# WKUP_CTRL_MMR0_WKUP_CTRL_MMR_CFG0_43000000h register map
Vendor: Texas Instruments
Registers are 32-bit, read-write, reset 0x0 unless marked. A register's access mark holds for its fields unless they carry their own. Offsets are as the file gives them; [hi:lo] are bit positions; {n}, {i} and the like mark numbered series.

## wkup_ctrl_mmr_CFG0 (part 3 of 3)
0x18368 WKUP_CTRL_MMRCFG0_IMMED_WAKE_TIMEOUT reset 0xEA — Determines the length of the timing window during which a monitored wakeup event will generate an IPOR. This ensures wakeup events occurring soon after PMIC_EN deactivation but before IORET state entry are recognized. After this window has expired, the external PMIC is expected to generate a POR based on PMIC_EN activation.The ImmediateWakeup Timeout window is disabled (no IPOR generated) if the wake_timeout_dis in WAKE_EVT_MON_CTRL is 1.
  [15:0] IMMED_WAKE_TIMEOUT_TIMEOUT_LENGTH — Specifies the number of HFOSC0 clock cycles during which wake monitoring logic will issue an internal POR. This timeout value must exceed the PMIC glitch filtering window for its PMIC_EN input. (Default value is 9 �s at 26 MHz HFOSC0) Reset Source: mod_por_rst_n
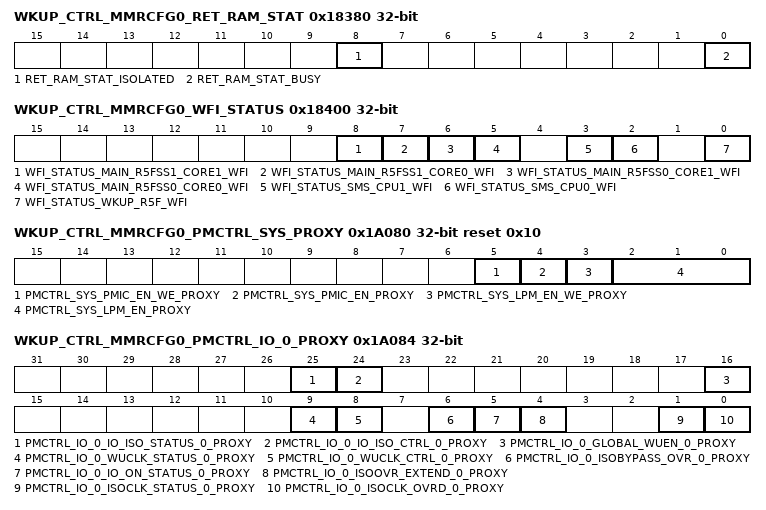
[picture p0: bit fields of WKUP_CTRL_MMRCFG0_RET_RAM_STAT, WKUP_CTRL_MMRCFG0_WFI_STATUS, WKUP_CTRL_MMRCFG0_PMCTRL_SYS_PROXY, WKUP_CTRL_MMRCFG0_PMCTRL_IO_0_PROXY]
0x18380 WKUP_CTRL_MMRCFG0_RET_RAM_STAT ro — Shows the Retention RAM Status
  [8] RET_RAM_STAT_ISOLATED — Indicates Retention RAM isolation state (when busy=0)Field values (others are reserved):1'b0 - RAM is not isolated1'b1 - RAM is isolated Reset Source: mod_por_rst_n
  [0] RET_RAM_STAT_BUSY — Indicates that Retention RAM state is transitioning. The RAM must not be accessed or the isolation powerdown sequence continued while busy=1Field values (others are reserved):1'b0 - RAM is in isolation state indicated by the isolated bit1'b1 - RAM isolation state is transitioning - do not access Reset Source: mod_por_rst_n
0x18400 WKUP_CTRL_MMRCFG0_WFI_STATUS ro — Allows inspection of WFI Status of all CPU Cores
  [8] WFI_STATUS_MAIN_R5FSS1_CORE1_WFI — WFI status of MAIN Cortex R5F_1 Core 1 (only valid when core is out of reset)Field values (others are reserved):1'b0 - UNKNOWN1'b1 - WFI_ACTIVE Reset Source: mod_por_rst_n
  [7] WFI_STATUS_MAIN_R5FSS1_CORE0_WFI — WFI status of MAIN Cortex R5F_1 Core 0 (only valid when core is out of reset)Field values (others are reserved):1'b0 - UNKNOWN1'b1 - WFI_ACTIVE Reset Source: mod_por_rst_n
  [6] WFI_STATUS_MAIN_R5FSS0_CORE1_WFI — WFI status of MAIN Cortex R5F_0 Core 0 (only valid when core is out of reset)Field values (others are reserved):1'b0 - UNKNOWN1'b1 - WFI_ACTIVE Reset Source: mod_por_rst_n
  [5] WFI_STATUS_MAIN_R5FSS0_CORE0_WFI — WFI status of MAIN Cortex R5F_0 Core 0 (only valid when core is out of reset)Field values (others are reserved):1'b0 - UNKNOWN1'b1 - WFI_ACTIVE Reset Source: mod_por_rst_n
  [3] WFI_STATUS_SMS_CPU1_WFI — WFI status of SMS Cortex M4F1 (only valid when CPU is out of reset)Field values (others are reserved):1'b0 - UNKNOWN1'b1 - WFI_ACTIVE Reset Source: mod_por_rst_n
  [2] WFI_STATUS_SMS_CPU0_WFI — WFI status of SMS Cortex M4F0 (only valid when CPU is out of reset)Field values (others are reserved):1'b0 - UNKNOWN1'b1 - WFI_ACTIVE Reset Source: mod_por_rst_n
  [0] WFI_STATUS_WKUP_R5F_WFI — WFI status of Device Manager Cortex R5F (only valid when CPU is out of reset)Field values (others are reserved):1'b0 - UNKNOWN1'b1 - WFI_ACTIVE Reset Source: mod_por_rst_n
0x18420 WKUP_CTRL_MMRCFG0_DS_MAIN reset 0xF — Reset Control and Main Power Domain Control
  [3:0] DS_MAIN_POR_PDOFF — Signal Puts main SMS, DebugSS and MainIP Power Domains into Power Off state, and asserts Main Power On Reset.Field values (others are reserved):4'b0110 - Off4'b1111 - On Reset Source: mcu_chip1_rst_n
0x18440 WKUP_CTRL_MMRCFG0_DS_DM_RESET reset 0xF — Reset Isolation for the Device Manager
  [3:0] DS_DM_RESET_MASK — Signal used to mask main domain resets from Device Manager / Wakeup and MCU IpsField values (others are reserved):4'b0110 - Masked4'b1111 - UnMasked Reset Source: mcu_chip1_rst_n
0x18460 WKUP_CTRL_MMRCFG0_DS_USB0_RESET reset 0xF — Reset Isolation for the USB0 Subsystem
  [3:0] DS_USB0_RESET_MASK — Signal used to block reset to the USBSS0Field values (others are reserved):4'b0110 - Masked4'b1111 - UnMasked Reset Source: mcu_chip1_rst_n
0x184A0 WKUP_CTRL_MMRCFG0_DM_GRP_CLKSTOP_REQ — Initiate Clockstop Request Sequence on WKUP Peripherals Activated in DM_CLKSTOP_EN
  [0] DM_GRP_CLKSTOP_REQ_REQ — Controls Assertion of Clockstop Request to IPs participating in Clockstop Req GroupField values (others are reserved):1'b0 - DEASSERT_REQ1'b1 - ASSERT_REQ Reset Source: mod_por_rst_n
0x18500 WKUP_CTRL_MMRCFG0_DEVICE_TYPE ro — Device Type as Decoded by SMS
  [7:4] DEVICE_TYPE_SMS_DEV_TYPE — Type of device reported by SMS. Values not listed should be interpreted as BAD.Field values (others are reserved):4'b0101 - DT_TEST4'b1001 - DT_EMU4'b1010 - DT_HS4'b0011 - DT_GP Reset Source: mod_por_rst_n
0x19008 WKUP_CTRL_MMRCFG0_LOCK6_KICK0
  [31:0] LOCK6_KICK0 — - KICK0 component Reset Source: mod_g_rst_n
0x1900C WKUP_CTRL_MMRCFG0_LOCK6_KICK1
  [31:0] LOCK6_KICK1 — - KICK1 component Reset Source: mod_g_rst_n
{0x19100+4i} WKUP_CTRL_MMRCFG0_CLAIMREG_P6_R{i}_READONLY ro (i=0..10)
  [31:0] CLAIMREG_P6_R{i}_READONLY — Claim bits for Partition 6 Reset Source: mod_g_rst_n
0x1A080 WKUP_CTRL_MMRCFG0_PMCTRL_SYS_PROXY reset 0x10 — Controls operation of the PMIC_LPM_EN pin
  [5] PMCTRL_SYS_PMIC_EN_WE_PROXY — Unused Field - Value is Don't Care Reset Source: mod_g_rst_n
  [4] PMCTRL_SYS_PMIC_EN_PROXY — Controls state of PMIC_LPM_EN_OUT when LPM_EN[2:0] is 000 Reset Source: mod_g_rst_n
  [3] PMCTRL_SYS_LPM_EN_WE_PROXY — Unused Field - Value is Don't Care Reset Source: mod_g_rst_n
  [2:0] PMCTRL_SYS_LPM_EN_PROXY — Controls whether PMIC_LPM_EN_OUT is driven by the pmic_en bit. Field values (others are reserved):3'b000 - PMIC_LPM_EN_OUT controlled by pmic_en bit. Reset Source: mod_g_rst_n
0x1A084 WKUP_CTRL_MMRCFG0_PMCTRL_IO_0_PROXY access per field — This register is writable only when LOCK6-KICK0:1 are unlocked
  [25] PMCTRL_IO_0_IO_ISO_STATUS_0_PROXY ro — IO ISO Status. Read 0: IO isolation not active. Read 1: IO isolation active.Reflects value of SMS input port io_isoack coming back fromIO pad ring. Reset Source: mod_g_rst_n
  [24] PMCTRL_IO_0_IO_ISO_CTRL_0_PROXY rw — IO ISO control. Writing this bit to 1 will kick off IO isolation. Reset Source: mod_g_rst_n
  [16] PMCTRL_IO_0_GLOBAL_WUEN_0_PROXY rw — Global IO wakeup enable. This is a gating condition to allindividual IO WUEN coming from control module. Gating isdone in the Io Logiclogic. 0:All individual IO WUEN are gated in the IO logic (override to 0). 1: All individual IO WUEN from control module are going to IOs.Map to SMS input port io_globalwkupen Reset Source: mod_g_rst_n
  [9] PMCTRL_IO_0_WUCLK_STATUS_0_PROXY ro — Reflects value of DM input port io_wuclkack coming backfrom IO pad ring. Reset Source: mod_g_rst_n
  [8] PMCTRL_IO_0_WUCLK_CTRL_0_PROXY rw — Direct control on WUCLKIN signal to IO pad ring.0:WUCLKINsignal is driven to 0.IO wakeup daisy chain is functional as wellas IO whose wakeup feature is enabled. 1:WUCLKIN signal is driven to 1. IO wakeup daisy chain is reset and is latching current pad states and WUEN inputs. Reset Source: mod_g_rst_n
  [6] PMCTRL_IO_0_ISOBYPASS_OVR_0_PROXY rw — This MMR bit drives directly DM output port io_isobypassundefined. Reset Source: mod_g_rst_n
  [5] PMCTRL_IO_0_IO_ON_STATUS_0_PROXY ro — Gives the functional status of the IO ring. Read 0: Part or all of the IOs are not in the ON state that is are in isolation state.Read 1: All IOs are in the ON state.io_on_status = assign 1 if (io_iso == 0 & io_isoack==0 &io_iso_clk == 0 & io_isoclk_ack = 0 ) else 0; Reset Source: mod_g_rst_n
  [4] PMCTRL_IO_0_ISOOVR_EXTEND_0_PROXY rw — This drives the SOC chain ISO-OVERRIDE global control.This bit drives directly the DM output port io_isoovrundefined. Atthe SOC level it is used to enable when 1 or gate-off when 0,the individual ISOOR for each IO. This operates as a globalenable/disable for the individual IOs.Control for IO isolation extension.'0' IO isolation is not extended. Transition happens as soon asautomatic restore is completed.'1' IO isolation is extended. The IOs whose ISOOVR bits havebeen individually set in their PADCFG MMRs will all get its IOisolation extended beyond the point when the initial IO daisychain isolation is released. Reset Source: mod_g_rst_n
  [1] PMCTRL_IO_0_ISOCLK_STATUS_0_PROXY ro — Reflects value of DM input port io_isoclkack coming backfrom IO pad ring. Reset Source: mod_g_rst_n
  [0] PMCTRL_IO_0_ISOCLK_OVRD_0_PROXY rw — Override control on ISOCLKIN signal to IO pad ring.When not overridden this signal is controlled by hardware only.0 ISOCLKIN signal is not override.1 ISOCLKIN signal is overridden to active value ('1'). Reset Source: mod_g_rst_n
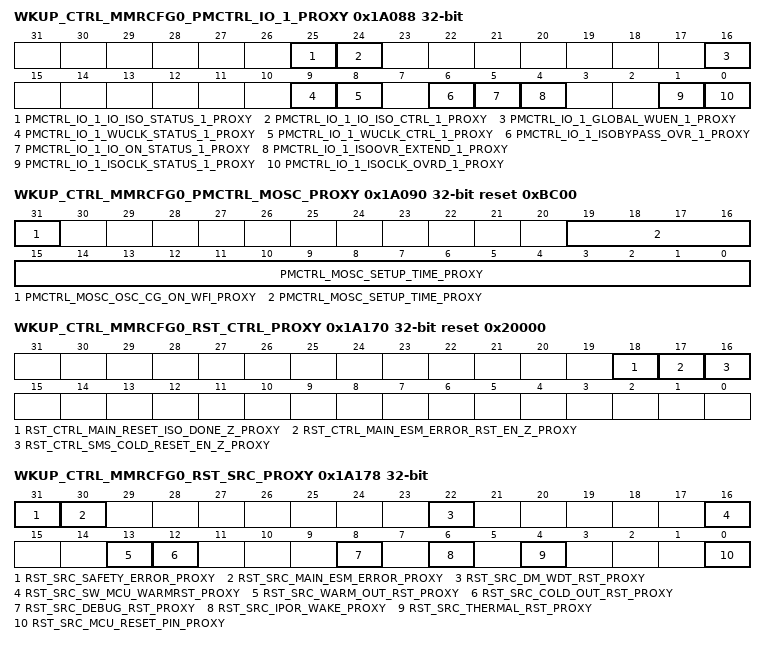
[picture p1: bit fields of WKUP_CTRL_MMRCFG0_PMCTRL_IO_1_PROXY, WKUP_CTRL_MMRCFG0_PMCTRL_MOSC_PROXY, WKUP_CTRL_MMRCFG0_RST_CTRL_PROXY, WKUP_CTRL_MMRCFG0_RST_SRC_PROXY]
0x1A088 WKUP_CTRL_MMRCFG0_PMCTRL_IO_1_PROXY access per field — This register is writable only when LOCK6-KICK0:1 are unlocked
  [25] PMCTRL_IO_1_IO_ISO_STATUS_1_PROXY ro — IO ISO Status. Read 0: IO isolation not active. Read 1: IO isolation active.Reflects value of DM input port io_isoack coming back fromIO pad ring. Reset Source: mod_g_rst_n
  [24] PMCTRL_IO_1_IO_ISO_CTRL_1_PROXY rw — IO ISO control. Writing this bit to 1 will kick off IO isolation. Reset Source: mod_g_rst_n
  [16] PMCTRL_IO_1_GLOBAL_WUEN_1_PROXY rw — Global IO wakeup enable. This is a gating condition to allindividual IO WUEN coming from control module. Gating isdone in the Spinner logic. 0:All individual IO WUEN are gatedin the Spinner logic (override to 0). 1: All individual IO WUENfrom control module are going to Ios.Map to DM input port io_globalwkupen Reset Source: mod_g_rst_n
  [9] PMCTRL_IO_1_WUCLK_STATUS_1_PROXY ro — Reflects value of DM input port io_wuclkack coming backfrom IO pad ring. Reset Source: mod_g_rst_n
  [8] PMCTRL_IO_1_WUCLK_CTRL_1_PROXY rw — Direct control on WUCLKIN signal to IO pad ring.0:WUCLKINsignal is driven to 0.IO wakeup daisy chain is functional as wellas IO whose wakeup feature is enabled. 1:WUCLKIN signal is driven to 1. IO wakeup daisy chain is reset and is latching current pad states and WUEN inputs. Reset Source: mod_g_rst_n
  [6] PMCTRL_IO_1_ISOBYPASS_OVR_1_PROXY rw — This MMR bit drives directly DM output port io_isobypassundefined. Reset Source: mod_g_rst_n
  [5] PMCTRL_IO_1_IO_ON_STATUS_1_PROXY ro — Gives the functional status of the IO ring. Read 0: Part or all ofthe Ios are not in the ON state that is are in isolation state.Read 1: All Ios are in the ON state.io_on_status = assign 1 if (io_iso == 0 & io_isoack==0 &io_iso_clk == 0 & io_isoclk_ack = 0 ) else 0; Reset Source: mod_g_rst_n
  [4] PMCTRL_IO_1_ISOOVR_EXTEND_1_PROXY rw — This drives the SOC chain ISO-OVERRIDE global control.This bit drives directly the DM output port io_isoovrundefined. Atthe SOC level it is used to enable when 1 or gate-off when 0,the individual ISOOR for each IO. This operates as a globalenable/disable for the individual IOs.Control for IO isolation extension.'0' IO isolation is not extended. Transition happens as soon asautomatic restore is completed.'1' IO isolation is extended. The IOs whose ISOOVR bits havebeen individually set in their PADCFG MMRs will all get its IOisolation extended beyond the point when the initial IO daisychain isolation is released. Reset Source: mod_g_rst_n
  [1] PMCTRL_IO_1_ISOCLK_STATUS_1_PROXY ro — Reflects value of DM input port io_isoclkack coming backfrom IO pad ring. Reset Source: mod_g_rst_n
  [0] PMCTRL_IO_1_ISOCLK_OVRD_1_PROXY rw — Override control on ISOCLKIN signal to IO pad ring.When not overridden this signal is controlled by hardware only.0 ISOCLKIN signal is not override.1 ISOCLKIN signal is overridden to active value ('1'). Reset Source: mod_g_rst_n
0x1A090 WKUP_CTRL_MMRCFG0_PMCTRL_MOSC_PROXY reset 0xBC00 — This register is writable only when LOCK6-KICK0:1 are unlocked
  [31] PMCTRL_MOSC_OSC_CG_ON_WFI_PROXY — To clock gate the main HFOSC, DM sets this bit then enters the WFI state at which time the HFOSC will be gated. Field values (others are reserved):1'b0 - INACTIVE1'b1 - ACTIVE Reset Source: mod_g_rst_n
  [19:0] PMCTRL_MOSC_SETUP_TIME_PROXY — Number of HFOSC clock cycles before HFOSC clock is ungated to the SOC (allows the HFOSC time to stabilize after starting up, before the SOC is clocked). Reset Source: mod_g_rst_n
0x1A098 WKUP_CTRL_MMRCFG0_PM_MISC_STATUS_PROXY ro — Reflects the progress of the request to clock-gate HFOSCvia MMR PMCTRL_MOSCundefined.
  [1:0] PM_MISC_STATUS_OSC_CG_STAT_PROXY — HFOSC Clock Gating StateField values (others are reserved):2'b00 - HFOSC_OFF2'b01 - HFOSC_OFF2ON (transition state)2'b10 - HFOSC_ON2OFF (transition state)2'b11 - HFOSC_ON Reset Source: mod_g_rst_n
0x1A170 WKUP_CTRL_MMRCFG0_RST_CTRL_PROXY reset 0x20000 — Controls Reset Assertion and Propogation
  [18] RST_CTRL_MAIN_RESET_ISO_DONE_Z_PROXY — Blocks Main Domain Warm Reset.Field values (others are reserved):1'b0 - PROPOGATE1'b1 - BLOCK Reset Source: main_chip1_rst_n
  [17] RST_CTRL_MAIN_ESM_ERROR_RST_EN_Z_PROXY — Block Reset of Main by ESMField values (others are reserved):1'b0 - PROPOGATE1'b1 - BLOCK Reset Source: main_chip1_rst_n
  [16] RST_CTRL_SMS_COLD_RESET_EN_Z_PROXY — Block Reset of Main by SMSField values (others are reserved):1'b0 - PROPOGATE1'b1 - BLOCK Reset Source: main_chip1_rst_n
0x1A174 WKUP_CTRL_MMRCFG0_RST_STAT_PROXY ro — Reset Status
  [0] RST_STAT_MCU_RESET_ISO_DONE_Z_PROXY — Indicates MCU Domain is in Reset Isolation When Active (Low)Field values (others are reserved):1'b0 - ISOLATION1'b1 - PASS_THROUGH Reset Source: main_chip1_rst_n
0x1A178 WKUP_CTRL_MMRCFG0_RST_SRC_PROXY ro — Captures Reason for Warm and Main Domain Power On ResetsRead Only Mirror of MCU CTRL MMR version. Clearing these bits must be done through the MCU CTRL MMR.
  [31] RST_SRC_SAFETY_ERROR_PROXY — Reset Caused by MCU ESM Error. Field values (others are reserved):1'b0 - UNKNOWN1'b1 - DETECTED Reset Source: main_chip1_rst_n
  [30] RST_SRC_MAIN_ESM_ERROR_PROXY — Reset Caused by Main ESM Error. Field values (others are reserved):1'b0 - UNKNOWN1'b1 - DETECTED Reset Source: main_chip1_rst_n
  [22] RST_SRC_DM_WDT_RST_PROXY — Watchdog Initiated Reset. Field values (others are reserved):1'b0 - UNKNOWN1'b1 - DETECTED Reset Source: main_chip1_rst_n
  [16] RST_SRC_SW_MCU_WARMRST_PROXY — Software Warm Reset. Field values (others are reserved):1'b0 - UNKNOWN1'b1 - DETECTED Reset Source: main_chip1_rst_n
  [13] RST_SRC_WARM_OUT_RST_PROXY — SMS Warm Reset. Field values (others are reserved):1'b0 - UNKNOWN1'b1 - DETECTED Reset Source: main_chip1_rst_n
  [12] RST_SRC_COLD_OUT_RST_PROXY — SMS Cold Reset. When set, indicates that a SMS Cold reset occurred and reset either MAIN or MCU domains (or both).Field values (others are reserved):1'b0 - UNKNOWN1'b1 - DETECTED Reset Source: main_chip1_rst_n
  [8] RST_SRC_DEBUG_RST_PROXY — Debug Subsystem Initiated Reset. Field values (others are reserved):1'b0 - UNKNOWN1'b1 - DETECTED Reset Source: main_chip1_rst_n
  [6] RST_SRC_IPOR_WAKE_PROXY — Wake Event Monitor Internal Power On Reset.Field values (others are reserved):1'b0 - UNKNOWN1'b1 - DETECTED Reset Source: main_chip1_rst_n
  [4] RST_SRC_THERMAL_RST_PROXY — Thermal Reset. Field values (others are reserved):1'b0 - UNKNOWN1'b1 - DETECTED Reset Source: main_chip1_rst_n
  [0] RST_SRC_MCU_RESET_PIN_PROXY — Rest Caused by MCU Reset Pin. Field values (others are reserved):1'b0 - UNKNOWN1'b1 - DETECTED Reset Source: main_chip1_rst_n
0x1A17C WKUP_CTRL_MMRCFG0_RST_MAGIC_WORD_PROXY ro — Read Only Mirror of MCU CTRL MMR version.After an MCU_PORz reset this bit field resets to 0x00000000. While this bit field remains 0x00000000 any warm reset from the Main Domain also propagates through the MCU domain.If the application does not require reset isolation of the MCU domain, it may leave this bit field with a value of 0x00000000.If the application does require reset isolation of the MCU domain after the initial boot, then the R5FSS CPU must write a nonzero value to the magic word. The actual value is left to software and different values maybe used to convey information, but in order to isolate the MCU domain from all Main domain warm reset sources that trigger main_resetz, the value must be non-zero.If the value is nonzero and one of the Main domain warm reset sources triggers main_resetz occurs in the main domain, the R5FSS will not be reset. The Main domain bootloader must read this valueto determine that the R5FSS is already initialized, and has configured reset isolation. The Main domain bootloader then also skips any initialization steps involving bootstrapping the R5FSS as it is is already running.Note that MCU_PORz reset is never blocked by a nonzero magic word.
  [31:0] RST_MAGIC_WORD_MCU_MAGIC_WORD_PROXY — Magic Word Indicating Status of MCU Subsystem Boot Reset Source: main_chip1_rst_n
0x1A180 WKUP_CTRL_MMRCFG0_WKUP0_EN_PROXY — Selects active wake-up sources
  [31:0] WKUP0_EN_WKUPEN_PROXY — Enables Wakeup from on-chip sources. In addition to values listed, any OR combination of the values is also valid.Field values (others are reserved):32'h00000001 - WKUP_I2C032'h00000002 - WKUP_USART032'h00000004 - MCU_GPIO032'h00000008 - DEBUGundefined - undefined32'h00000020 - WKUP_TIMER032'h00000040 - WKUP_TIMER132'h00000080 - WKUP_RTC32'h00000100 - MAIN_RESET_REQz32'h00000200 - USB0_IN_BANDundefined - undefined32'h00010000 - MAIN_IO_DAISY_CHAIN32'h00020000 - MCU_IO_DAISY_CHAIN32'h00040000 - CANUART_IO_DAISY_CHAIN Reset Source: mod_g_rst_n
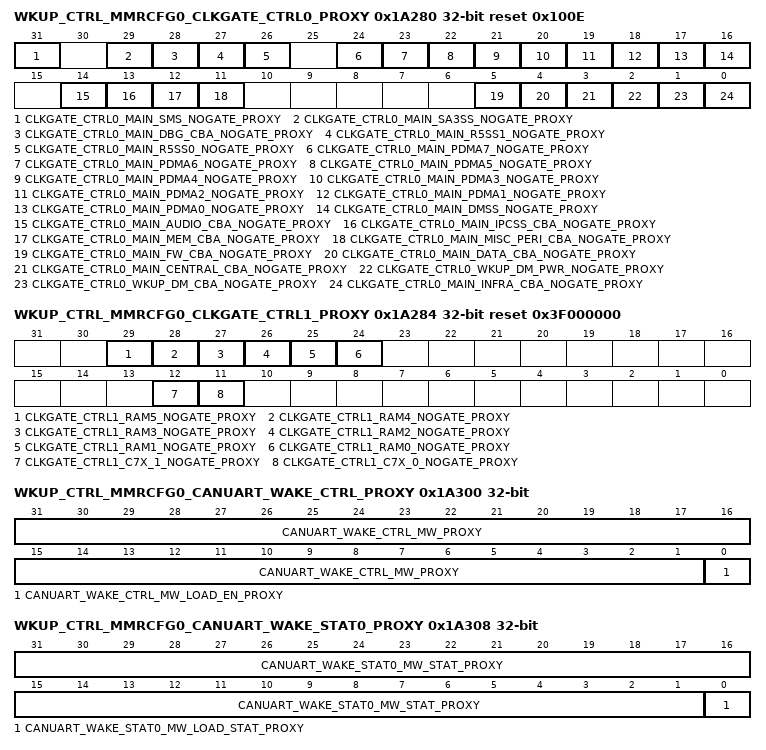
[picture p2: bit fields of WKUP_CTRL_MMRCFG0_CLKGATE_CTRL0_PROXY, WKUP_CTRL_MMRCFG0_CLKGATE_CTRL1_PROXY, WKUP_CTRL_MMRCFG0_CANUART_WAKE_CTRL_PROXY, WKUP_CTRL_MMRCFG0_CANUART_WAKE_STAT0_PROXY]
0x1A280 WKUP_CTRL_MMRCFG0_CLKGATE_CTRL0_PROXY reset 0x100E — Controls the power clock gating feature of modules and busses
  [31] CLKGATE_CTRL0_MAIN_SMS_NOGATE_PROXY — MAIN domain SMS auto clock gate on idle disable. Field values (others are reserved):1'b0 - Auto clock gating enabled1'b1 - Auto clock gating disabled Reset Source: mod_por_rst_n
  [29] CLKGATE_CTRL0_MAIN_SA3SS_NOGATE_PROXY — MAIN domain SA3SS auto clock gate on idle disable. Field values (others are reserved):1'b0 - Auto clock gating enabled1'b1 - Auto clock gating disabled Reset Source: mod_por_rst_n
  [28] CLKGATE_CTRL0_MAIN_DBG_CBA_NOGATE_PROXY — MAIN domain Debug CBASS auto clock gate on idle disable. Field values (others are reserved):1'b0 - Auto clock gating enabled1'b1 - Auto clock gating disabled Reset Source: mod_por_rst_n
  [27] CLKGATE_CTRL0_MAIN_R5SS1_NOGATE_PROXY — MAIN domain R5SS1 auto clock gate on idle disableField values (others are reserved):1'b0 - Auto clock gating enabled1'b1 - Auto clock gating disabled Reset Source: mod_por_rst_n
  [26] CLKGATE_CTRL0_MAIN_R5SS0_NOGATE_PROXY — MAIN domain R5SS0 auto clock gate on idle disableField values (others are reserved):1'b0 - Auto clock gating enabled1'b1 - Auto clock gating disabled Reset Source: mod_por_rst_n
  [24] CLKGATE_CTRL0_MAIN_PDMA7_NOGATE_PROXY — MAIN domain PDMA7 (ASRC11) auto clock gate on idle disable. Field values (others are reserved):1'b1 - Auto clock gating disabled Reset Source: mod_por_rst_n
  [23] CLKGATE_CTRL0_MAIN_PDMA6_NOGATE_PROXY — MAIN domain PDMA6 (ASRC0) auto clock gate on idle disable. Field values (others are reserved):1'b0 - Auto clock gating enabled1'b1 - Auto clock gating disabled1'b0 - Auto clock gating enabled Reset Source: mod_por_rst_n
  [22] CLKGATE_CTRL0_MAIN_PDMA5_NOGATE_PROXY — MAIN domain PDMA5 (ADC) auto clock gate on idle disable. Field values (others are reserved):1'b0 - Auto clock gating enabled1'b1 - Auto clock gating disabled Reset Source: mod_por_rst_n
  [21] CLKGATE_CTRL0_MAIN_PDMA4_NOGATE_PROXY — MAIN domain PDMA4 (SPI/MCAN 1) auto clock gate on idle disable. Field values (others are reserved):1'b0 - Auto clock gating enabled1'b1 - Auto clock gating disabled Reset Source: mod_por_rst_n
  [20] CLKGATE_CTRL0_MAIN_PDMA3_NOGATE_PROXY — MAIN domain PDMA3 (McASP1) auto clock gate on idle disable. Field values (others are reserved):1'b0 - Auto clock gating enabled1'b1 - Auto clock gating disabled Reset Source: mod_por_rst_n
  [19] CLKGATE_CTRL0_MAIN_PDMA2_NOGATE_PROXY — MAIN domain PDMA2 (McASP0) auto clock gate on idle disable. Field values (others are reserved):1'b0 - Auto clock gating enabled1'b1 - Auto clock gating disabled Reset Source: mod_por_rst_n
  [18] CLKGATE_CTRL0_MAIN_PDMA1_NOGATE_PROXY — MAIN domain PDMA1 (UART) auto clock gate on idle disable. Field values (others are reserved):1'b0 - Auto clock gating enabled1'b1 - Auto clock gating disabled Reset Source: mod_por_rst_n
  [17] CLKGATE_CTRL0_MAIN_PDMA0_NOGATE_PROXY — MAIN domain PDMA0 (SPI/MCAN 0) auto clock gate on idle disable. Field values (others are reserved):1'b0 - Auto clock gating enabled1'b1 - Auto clock gating disabled Reset Source: mod_por_rst_n
  [16] CLKGATE_CTRL0_MAIN_DMSS_NOGATE_PROXY — MAIN domain DMSS auto clock gate on idle disable. Field values (others are reserved):1'b0 - Auto clock gating enabled1'b1 - Auto clock gating disabled Reset Source: mod_por_rst_n
  [14] CLKGATE_CTRL0_MAIN_AUDIO_CBA_NOGATE_PROXY — MAIN domain Infrastructure bus (AUDIO) auto clock gate on idle disable. Field values (others are reserved):1'b0 - Auto clock gating enabled1'b1 - Auto clock gating disabled Reset Source: mod_por_rst_n
  [13] CLKGATE_CTRL0_MAIN_IPCSS_CBA_NOGATE_PROXY — MAIN domain Infrastructure CBASS auto clock gate on idle disable. Field values (others are reserved):1'b0 - Auto clock gating enabled1'b1 - Auto clock gating disabled Reset Source: mod_por_rst_n
  [12] CLKGATE_CTRL0_MAIN_MEM_CBA_NOGATE_PROXY — MAIN domain infrastructure bus (MEM) auto cloclk gate on idle disable Reset Source: mod_por_rst_n
  [11] CLKGATE_CTRL0_MAIN_MISC_PERI_CBA_NOGATE_PROXY — MAIN domain Infrastructure bus (Misc Peripheral) auto clock gate on idle disable. Field values (others are reserved):1'b0 - Auto clock gating enabled1'b1 - Auto clock gating disabled Reset Source: mod_por_rst_n
  [5] CLKGATE_CTRL0_MAIN_FW_CBA_NOGATE_PROXY — MAIN domain data bus auto clock gate on idle disable. Field values (others are reserved):1'b0 - Auto clock gating enabled1'b1 - Auto clock gating disabled Reset Source: mod_por_rst_n
  [4] CLKGATE_CTRL0_MAIN_DATA_CBA_NOGATE_PROXY — MAIN domain data bus auto clock gate on idle disable. Field values (others are reserved):1'b0 - Auto clock gating enabled1'b1 - Auto clock gating disabled Reset Source: mod_por_rst_n
  [3] CLKGATE_CTRL0_MAIN_CENTRAL_CBA_NOGATE_PROXY — WKUP domain Infrastructure ECC aggregator auto clock gate on idle disable. Field values (others are reserved):1'b0 - Auto clock gating enabled1'b1 - Auto clock gating disabled Reset Source: mod_por_rst_n
  [2] CLKGATE_CTRL0_WKUP_DM_PWR_NOGATE_PROXY — WKUP domain Device Manager auto clock gate on idle disable.Field values (others are reserved):1'b0 - Auto clock gating enabled1'b1 - Auto clock gating disabled Reset Source: mod_por_rst_n
  [1] CLKGATE_CTRL0_WKUP_DM_CBA_NOGATE_PROXY — WKUP domain device manager CBA auto clock gate on idle disable.Field values (others are reserved):1'b0 - Auto clock gating enabled1'b1 - Auto clock gating disabled Reset Source: mod_por_rst_n
  [0] CLKGATE_CTRL0_MAIN_INFRA_CBA_NOGATE_PROXY — MAIN domain Infrastructure bus auto clock gate on idle disable. Field values (others are reserved):1'b0 - Auto clock gating enabled1'b1 - Auto clock gating disabled Reset Source: mod_por_rst_n
0x1A284 WKUP_CTRL_MMRCFG0_CLKGATE_CTRL1_PROXY reset 0x3F000000 — Controls the power clock gating feature of modules and busses
  [29] CLKGATE_CTRL1_RAM5_NOGATE_PROXY — MAIN SRAM bank 5 auto clockgate on idle disableField values (others are reserved):1'b0 - Auto clock gating enabled1'b1 - Auto clock gating disabled Reset Source: mod_por_rst_n
  [28] CLKGATE_CTRL1_RAM4_NOGATE_PROXY — MAIN SRAM bank 4 auto clockgate on idle disableField values (others are reserved):1'b0 - Auto clock gating enabled1'b1 - Auto clock gating disabled Reset Source: mod_por_rst_n
  [27] CLKGATE_CTRL1_RAM3_NOGATE_PROXY — MAIN SRAM bank 5 auto clockgate on idle disableField values (others are reserved):1'b0 - Auto clock gating enabled1'b1 - Auto clock gating disabled Reset Source: mod_por_rst_n
  [26] CLKGATE_CTRL1_RAM2_NOGATE_PROXY — MAIN SRAM bank 2 auto clockgate on idle disableField values (others are reserved):1'b0 - Auto clock gating enabled1'b1 - Auto clock gating disabled Reset Source: mod_por_rst_n
  [25] CLKGATE_CTRL1_RAM1_NOGATE_PROXY — MAIN SRAM bank 1 auto clockgate on idle disableField values (others are reserved):1'b0 - Auto clock gating enabled1'b1 - Auto clock gating disabled Reset Source: mod_por_rst_n
  [24] CLKGATE_CTRL1_RAM0_NOGATE_PROXY — MAIN SRAM bank 0 auto clockgate on idle disableField values (others are reserved):1'b0 - Auto clock gating enabled1'b1 - Auto clock gating disabled Reset Source: mod_por_rst_n
  [12] CLKGATE_CTRL1_C7X_1_NOGATE_PROXY — C7x_1 auto clock gate on idle disable. Field values (others are reserved):1'b0 - Auto clock gating enabled1'b1 - Auto clock gating disabled Reset Source: mod_por_rst_n
  [11] CLKGATE_CTRL1_C7X_0_NOGATE_PROXY — C7x_0 auto clock gate on idle disable. Reset Source: mod_por_rst_n
0x1A300 WKUP_CTRL_MMRCFG0_CANUART_WAKE_CTRL_PROXY — Controls the operation of IO wakeup on the CANUART pins.
  [31:1] CANUART_WAKE_CTRL_MW_PROXY — CANUART IO magic word. The lower 23 bits determine if the device enters CANUART IO isolation when mw_load_en is set.If the lower 23 bits match the ACTIVATE value (0x5AAAAA), then CANUART IO Isolation is entered, any other value will prevent entry.The upper 8 bits of this register are software defined and do not determine whether or not CANUART IO isolation is entered. Field values (others are reserved):31'h005AAAAA - ACTIVATE31'h00000000 - DEACTIVATE Reset Source: mcu_chip1_rst_n
  [0] CANUART_WAKE_CTRL_MW_LOAD_EN_PROXY — Magic word load enableSetting this bit loads and locks the mw field for CANUART IO isolation. If the mw field matches ACTIVATE, CANUART IO Isolation is initiated.Field values (others are reserved):1'b0 - UNLOCK1'b1 - LOCK_AND_LOAD Reset Source: mcu_chip1_rst_n
0x1A308 WKUP_CTRL_MMRCFG0_CANUART_WAKE_STAT0_PROXY ro — Provides the status of CANUART_WAKE control bits.These bits come from the daisy-chain wakeup logic and maintain their value across core powerdown if isolation is activated.
  [31:1] CANUART_WAKE_STAT0_MW_STAT_PROXY — CANUART magic word statusIndicates the latched value of the mw field. Reset Source: mod_por_rst_n
  [0] CANUART_WAKE_STAT0_MW_LOAD_STAT_PROXY — Magic word load status.Indicates the latched value of the mw_load_en bit Reset Source: mod_por_rst_n
0x1A30C WKUP_CTRL_MMRCFG0_CANUART_WAKE_STAT1_PROXY ro — Provides CANUART IO isolation status.These bits come from the daisy-chain wakeup logic and maintain their value across core powerdown if isolation is activated
  [0] CANUART_WAKE_STAT1_CANUART_IO_MODE_PROXY — Indicates if CANUART IO wakeup mode is enabled.Field values (others are reserved):1'b0 - INACTIVE1'b1 - ACTIVATED Reset Source: mod_por_rst_n
0x1A310 WKUP_CTRL_MMRCFG0_CANUART_WAKE_OFF_MODE_PROXY
  [31:0] CANUART_WAKE_OFF_MODE_MW_PROXY — magic word Reset Source: mod_por_rst_n
0x1A318 WKUP_CTRL_MMRCFG0_CANUART_WAKE_OFF_MODE_STAT_PROXY ro
  [31:0] CANUART_WAKE_OFF_MODE_STAT_MW_PROXY — returned magic word Reset Source: mod_por_rst_n
0x1A320 WKUP_CTRL_MMRCFG0_CANUART_WAKE_RESUME_KEY_PROXY_j
  [31:0] KEYVAL_PROXY — key value Reset Source: mod_por_rst_n
0x1A340 WKUP_CTRL_MMRCFG0_CANUART_WAKE_RESUME_KEY_STAT_PROXY_j ro
  [31:0] KEYVAL_PROXY — returned key value Reset Source: mod_por_rst_n
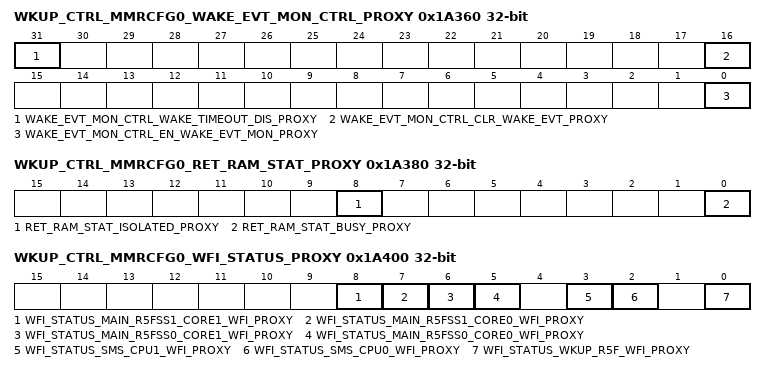
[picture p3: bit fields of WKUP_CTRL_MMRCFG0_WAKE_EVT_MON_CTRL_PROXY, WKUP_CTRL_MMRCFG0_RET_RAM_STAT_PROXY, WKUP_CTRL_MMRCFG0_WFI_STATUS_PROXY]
0x1A360 WKUP_CTRL_MMRCFG0_WAKE_EVT_MON_CTRL_PROXY — Controls monitoring of wake events during IO retention entry/exit
  [31] WAKE_EVT_MON_CTRL_WAKE_TIMEOUT_DIS_PROXY — Disable wakeup event timeout window. Field values (others are reserved):1'b0 - An Internal POR is generated when a wakeup event is detected by the IORET entry/exit wakeup event monitor before the Immediate Wakeup Timeout window expiration1'b1 - The immediate wakeup timeout window is disabled. Reset Source: mod_por_rst_n
  [16] WAKE_EVT_MON_CTRL_CLR_WAKE_EVT_PROXY — Clear wakeup events. Write 1 to clear all wakeup events. Read always returns 0.Field values (others are reserved):1'b0 - Read value. Writing 0 has no effect1'b1 - Clear all wake events Reset Source: mod_por_rst_n
  [0] WAKE_EVT_MON_CTRL_EN_WAKE_EVT_MON_PROXY — Enable wakeup event monitoring. Field values (others are reserved):1'b0 - All IORET entry/exit wakeup event monitoring is disabled1'b1 - Enable wakeup event monitoring during IORET entry/exit. The pins to be monitored are determined by the corresponding PADCONFIG register settings Reset Source: mod_por_rst_n
0x1A364 WKUP_CTRL_MMRCFG0_INTRN_POR_DUR_PROXY reset 0x20 — Determines how long the IPOR generated by IORET entry/exit wakeup monitoring will be asserted
  [7:0] INTRN_POR_DUR_IPOR_LEN_PROXY — Specifies the number of HFOSC0 clock cycles to assert IPORz (low) when the wake monitoring logic detects a wakeup event. This value must exceed the minimum PORz period for the device with stable power supplies and reference clocks (1200 ns) Reset Source: mod_por_rst_n
0x1A368 WKUP_CTRL_MMRCFG0_IMMED_WAKE_TIMEOUT_PROXY reset 0xEA — Determines the length of the timing window during which a monitored wakeup event will generate an IPOR. This ensures wakeup events occurring soon after PMIC_EN deactivation but before IORET state entry are recognized. After this window has expired, the external PMIC is expected to generate a POR based on PMIC_EN activation.The ImmediateWakeup Timeout window is disabled (no IPOR generated) if the wake_timeout_dis in WAKE_EVT_MON_CTRL is 1.
  [15:0] IMMED_WAKE_TIMEOUT_TIMEOUT_LENGTH_PROXY — Specifies the number of HFOSC0 clock cycles during which wake monitoring logic will issue an internal POR. This timeout value must exceed the PMIC glitch filtering window for its PMIC_EN input. (Default value is 9 �s at 26 MHz HFOSC0) Reset Source: mod_por_rst_n
0x1A380 WKUP_CTRL_MMRCFG0_RET_RAM_STAT_PROXY ro — Shows the Retention RAM Status
  [8] RET_RAM_STAT_ISOLATED_PROXY — Indicates Retention RAM isolation state (when busy=0)Field values (others are reserved):1'b0 - RAM is not isolated1'b1 - RAM is isolated Reset Source: mod_por_rst_n
  [0] RET_RAM_STAT_BUSY_PROXY — Indicates that Retention RAM state is transitioning. The RAM must not be accessed or the isolation powerdown sequence continued while busy=1Field values (others are reserved):1'b0 - RAM is in isolation state indicated by the isolated bit1'b1 - RAM isolation state is transitioning - do not access Reset Source: mod_por_rst_n
0x1A400 WKUP_CTRL_MMRCFG0_WFI_STATUS_PROXY ro — Allows inspection of WFI Status of all CPU Cores
  [8] WFI_STATUS_MAIN_R5FSS1_CORE1_WFI_PROXY — WFI status of MAIN Cortex R5F_1 Core 1 (only valid when core is out of reset)Field values (others are reserved):1'b0 - UNKNOWN1'b1 - WFI_ACTIVE Reset Source: mod_por_rst_n
  [7] WFI_STATUS_MAIN_R5FSS1_CORE0_WFI_PROXY — WFI status of MAIN Cortex R5F_1 Core 0 (only valid when core is out of reset)Field values (others are reserved):1'b0 - UNKNOWN1'b1 - WFI_ACTIVE Reset Source: mod_por_rst_n
  [6] WFI_STATUS_MAIN_R5FSS0_CORE1_WFI_PROXY — WFI status of MAIN Cortex R5F_0 Core 0 (only valid when core is out of reset)Field values (others are reserved):1'b0 - UNKNOWN1'b1 - WFI_ACTIVE Reset Source: mod_por_rst_n
  [5] WFI_STATUS_MAIN_R5FSS0_CORE0_WFI_PROXY — WFI status of MAIN Cortex R5F_0 Core 0 (only valid when core is out of reset)Field values (others are reserved):1'b0 - UNKNOWN1'b1 - WFI_ACTIVE Reset Source: mod_por_rst_n
  [3] WFI_STATUS_SMS_CPU1_WFI_PROXY — WFI status of SMS Cortex M4F1 (only valid when CPU is out of reset)Field values (others are reserved):1'b0 - UNKNOWN1'b1 - WFI_ACTIVE Reset Source: mod_por_rst_n
  [2] WFI_STATUS_SMS_CPU0_WFI_PROXY — WFI status of SMS Cortex M4F0 (only valid when CPU is out of reset)Field values (others are reserved):1'b0 - UNKNOWN1'b1 - WFI_ACTIVE Reset Source: mod_por_rst_n
  [0] WFI_STATUS_WKUP_R5F_WFI_PROXY — WFI status of Device Manager Cortex R5F (only valid when CPU is out of reset)Field values (others are reserved):1'b0 - UNKNOWN1'b1 - WFI_ACTIVE Reset Source: mod_por_rst_n
0x1A420 WKUP_CTRL_MMRCFG0_DS_MAIN_PROXY reset 0xF — Reset Control and Main Power Domain Control
  [3:0] DS_MAIN_POR_PDOFF_PROXY — Signal Puts main SMS, DebugSS and MainIP Power Domains into Power Off state, and asserts Main Power On Reset.Field values (others are reserved):4'b0110 - Off4'b1111 - On Reset Source: mcu_chip1_rst_n
0x1A440 WKUP_CTRL_MMRCFG0_DS_DM_RESET_PROXY reset 0xF — Reset Isolation for the Device Manager
  [3:0] DS_DM_RESET_MASK_PROXY — Signal used to mask main domain resets from Device Manager / Wakeup and MCU IpsField values (others are reserved):4'b0110 - Masked4'b1111 - UnMasked Reset Source: mcu_chip1_rst_n
0x1A460 WKUP_CTRL_MMRCFG0_DS_USB0_RESET_PROXY reset 0xF — Reset Isolation for the USB0 Subsystem
  [3:0] DS_USB0_RESET_MASK_PROXY — Signal used to block reset to the USBSS0Field values (others are reserved):4'b0110 - Masked4'b1111 - UnMasked Reset Source: mcu_chip1_rst_n
0x1A4A0 WKUP_CTRL_MMRCFG0_DM_GRP_CLKSTOP_REQ_PROXY — Initiate Clockstop Request Sequence on WKUP Peripherals Activated in DM_CLKSTOP_EN
  [0] DM_GRP_CLKSTOP_REQ_REQ_PROXY — Controls Assertion of Clockstop Request to IPs participating in Clockstop Req GroupField values (others are reserved):1'b0 - DEASSERT_REQ1'b1 - ASSERT_REQ Reset Source: mod_por_rst_n
0x1A500 WKUP_CTRL_MMRCFG0_DEVICE_TYPE_PROXY ro — Device Type as Decoded by SMS
  [7:4] DEVICE_TYPE_SMS_DEV_TYPE_PROXY — Type of device reported by SMS. Values not listed should be interpreted as BAD.Field values (others are reserved):4'b0101 - DT_TEST4'b1001 - DT_EMU4'b1010 - DT_HS4'b0011 - DT_GP Reset Source: mod_por_rst_n
0x1B008 WKUP_CTRL_MMRCFG0_LOCK6_KICK0_PROXY
  [31:0] LOCK6_KICK0_PROXY — - KICK0 component Reset Source: mod_g_rst_n
0x1B00C WKUP_CTRL_MMRCFG0_LOCK6_KICK1_PROXY
  [31:0] LOCK6_KICK1_PROXY — - KICK1 component Reset Source: mod_g_rst_n
{0x1B100+4i} WKUP_CTRL_MMRCFG0_CLAIMREG_P6_R{i} (i=0..10)
  [31:0] CLAIMREG_P6_R{i} — Claim bits for Partition 6 Reset Source: mod_g_rst_n
0x1D008 WKUP_CTRL_MMRCFG0_LOCK7_KICK0
  [31:0] LOCK7_KICK0 — - KICK0 component Reset Source: mod_g_rst_n
0x1D00C WKUP_CTRL_MMRCFG0_LOCK7_KICK1
  [31:0] LOCK7_KICK1 — - KICK1 component Reset Source: mod_g_rst_n
{0x1D100+4i} WKUP_CTRL_MMRCFG0_CLAIMREG_P7_R{i}_READONLY ro (i=0..2)
  [31:0] CLAIMREG_P7_R{i}_READONLY — Claim bits for Partition 7 Reset Source: mod_g_rst_n
0x1F008 WKUP_CTRL_MMRCFG0_LOCK7_KICK0_PROXY
  [31:0] LOCK7_KICK0_PROXY — - KICK0 component Reset Source: mod_g_rst_n
0x1F00C WKUP_CTRL_MMRCFG0_LOCK7_KICK1_PROXY
  [31:0] LOCK7_KICK1_PROXY — - KICK1 component Reset Source: mod_g_rst_n
{0x1F100+4i} WKUP_CTRL_MMRCFG0_CLAIMREG_P7_R{i} (i=0..2)
  [31:0] CLAIMREG_P7_R{i} — Claim bits for Partition 7 Reset Source: mod_g_rst_n
